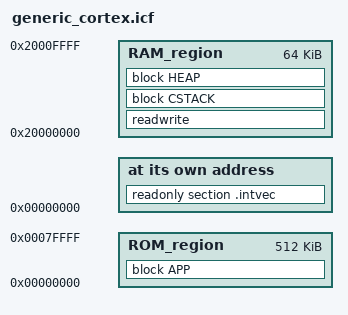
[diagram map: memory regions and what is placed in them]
/*
 * Generic IAR ILINK configuration for Arm Cortex with checksum placeholder
 *
 * This file is a slimmed down version of arm/config/generic_cortex.icf
 * and includes modifications to accomodate a placeholder in flash,
 * right after the application, for the checksum generated by IAR ELF tool.
 *
 *
 * Refer to the reusable block placement for the ROM_region near line 42.
 */

/*###ICF### Section handled by ICF editor, don't touch! ****/
/*-Editor annotation file-*/
/* IcfEditorFile="$TOOLKIT_DIR$\config\ide\IcfEditor\cortex_v1_4.xml" */
/*-Specials-*/
define symbol __ICFEDIT_intvec_start__ = 0x00000000;
/*-Memory Regions-*/
define symbol __ICFEDIT_region_ROM_start__ = 0x00000000;
define symbol __ICFEDIT_region_ROM_end__   = 0x0007FFFF;
define symbol __ICFEDIT_region_RAM_start__ = 0x20000000;
define symbol __ICFEDIT_region_RAM_end__   = 0x2000FFFF;
/*-Sizes-*/
define symbol __ICFEDIT_size_cstack__     = 0x400;
define symbol __ICFEDIT_size_heap__       = 0x200;
/**** End of ICF editor section. ###ICF###*/

define memory mem with size = 4G;
define region ROM_region = mem:[from __ICFEDIT_region_ROM_start__ to __ICFEDIT_region_ROM_end__];
define region RAM_region = mem:[from __ICFEDIT_region_RAM_start__ to __ICFEDIT_region_RAM_end__];

do not initialize  { section .noinit };
initialize by copy { readwrite };

if (isdefinedsymbol(__USE_DLIB_PERTHREAD))
{
  // Required in a multi-threaded application
  initialize by copy with packing = none { section __DLIB_PERTHREAD };
}

place at address mem:__ICFEDIT_intvec_start__ { readonly section .intvec };

// This if() block is the relevant change for ielftool's checksum placement
if (!isempty(ROM_region))
{
  // Application block with ielftool checksum placeholder at end
  define block APP with fixed order {
    readonly,
    ro section .checksum
  };

  place in ROM_region  { block APP };
}

if (!isempty(RAM_region))
{
  define block CSTACK     with alignment = 8, size = __ICFEDIT_size_cstack__     { };
  define block HEAP       with alignment = 8, size = __ICFEDIT_size_heap__       { };

  place in RAM_region  {
    readwrite,
    block CSTACK,
    block HEAP
  };
}

